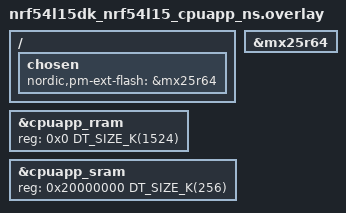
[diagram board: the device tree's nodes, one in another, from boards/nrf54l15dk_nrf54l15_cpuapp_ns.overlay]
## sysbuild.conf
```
SB_CONFIG_PM_EXTERNAL_FLASH_MCUBOOT_SECONDARY=y
SB_CONFIG_PM_OVERRIDE_EXTERNAL_DRIVER_CHECK=y
```

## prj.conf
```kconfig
# nothing here
# Enable MCUBoot.
CONFIG_BOOTLOADER_MCUBOOT=y
```

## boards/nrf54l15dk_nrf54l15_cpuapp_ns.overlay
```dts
/*
 * Copyright (c) 2024 Nordic Semiconductor ASA
 *
 * SPDX-License-Identifier: LicenseRef-Nordic-5-Clause
 */

/ {

	chosen {
		nordic,pm-ext-flash = &mx25r64;
	};
};

// restore full RRAM and SRAM space - by default some parts are dedicated to FLRP
&cpuapp_rram {
	reg = <0x0 DT_SIZE_K(1524)>;
};

&cpuapp_sram {
	reg = <0x20000000 DT_SIZE_K(256)>;
	ranges = <0x0 0x20000000  0x40000>;
};

&mx25r64 {
	status = "okay";
};
```

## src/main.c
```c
/*
 * Copyright (c) 2012-2014 Wind River Systems, Inc.
 *
 * SPDX-License-Identifier: Apache-2.0
 */

#include <stdio.h>
// volatile const char arr[712624] __attribute__ ((section (".text")));

int main(void)
{
	printf("Hello World! %s\n", CONFIG_BOARD_TARGET);
	// printf("arr: %c\n", arr[0]);
	return 0;
}
```
